# RP1 register map
Vendor: Raspberry Pi; File version: 0.1
CPU: CM3, little endian, MPU, no FPU, 58 interrupts
Registers are access not given, no defined reset value unless marked. A register's access mark holds for its fields unless they carry their own. Offsets are from the block's base; [hi:lo] are bit positions; <NAME> marks a mode.

## UART0
Base 0x40030000
Same registers: UART1 0x40034000, UART2 0x40038000, UART3 0x4003C000, UART4 0x40040000, UART5 0x40044000
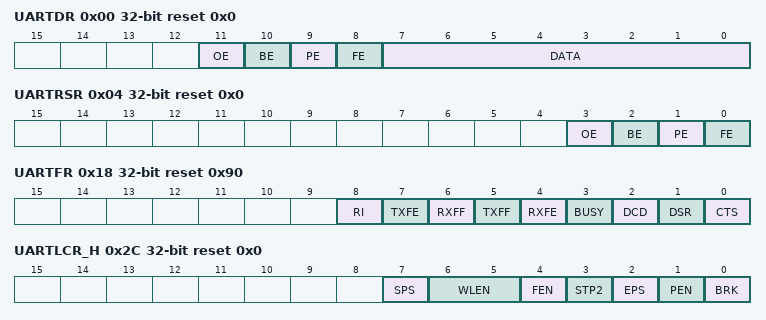
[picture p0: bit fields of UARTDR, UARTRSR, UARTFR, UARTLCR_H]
0x00 UARTDR 32-bit access per field reset 0x0 — Data Register, UARTDR
  [11] OE ro — Overrun error. This bit is set to 1 if data is received and the receive FIFO is already full. This is cleared to 0 once there is an empty space in the FIFO and a new character can be written to it.
  [10] BE ro — Break error. This bit is set to 1 if a break condition was detected, indicating that the received data input was held LOW for longer than a full-word transmission time (defined as start, data, parity and stop bits). In FIFO mode, this error is associated with the character at the top of the FIFO. When a break occurs, only one 0 character is loaded into the FIFO. The next character is only enabled after the receive data input goes to a 1 (marking state), and the next valid start bit is received.
  [9] PE ro — Parity error. When set to 1, it indicates that the parity of the received data character does not match the parity that the EPS and SPS bits in the Line Control Register, UARTLCR_H. In FIFO mode, this error is associated with the character at the top of the FIFO.
  [8] FE ro — Framing error. When set to 1, it indicates that the received character did not have a valid stop bit (a valid stop bit is 1). In FIFO mode, this error is associated with the character at the top of the FIFO.
  [7:0] DATA rw — Receive (read) data character. Transmit (write) data character.
0x04 UARTRSR 32-bit rw reset 0x0 — Receive Status Register/Error Clear Register, UARTRSR/UARTECR
  [3] OE write-1-clears — Overrun error. This bit is set to 1 if data is received and the FIFO is already full. This bit is cleared to 0 by a write to UARTECR. The FIFO contents remain valid because no more data is written when the FIFO is full, only the contents of the shift register are overwritten. The CPU must now read the data, to empty the FIFO.
  [2] BE write-1-clears — Break error. This bit is set to 1 if a break condition was detected, indicating that the received data input was held LOW for longer than a full-word transmission time (defined as start, data, parity, and stop bits). This bit is cleared to 0 after a write to UARTECR. In FIFO mode, this error is associated with the character at the top of the FIFO. When a break occurs, only one 0 character is loaded into the FIFO. The next character is only enabled after the receive data input goes to a 1 (marking state) and the next valid start bit is received.
  [1] PE write-1-clears — Parity error. When set to 1, it indicates that the parity of the received data character does not match the parity that the EPS and SPS bits in the Line Control Register, UARTLCR_H. This bit is cleared to 0 by a write to UARTECR. In FIFO mode, this error is associated with the character at the top of the FIFO.
  [0] FE write-1-clears — Framing error. When set to 1, it indicates that the received character did not have a valid stop bit (a valid stop bit is 1). This bit is cleared to 0 by a write to UARTECR. In FIFO mode, this error is associated with the character at the top of the FIFO.
0x18 UARTFR 32-bit ro reset 0x90 — Flag Register, UARTFR
  [8] RI — Ring indicator. This bit is the complement of the UART ring indicator, nUARTRI, modem status input. That is, the bit is 1 when nUARTRI is LOW.
  [7] TXFE — Transmit FIFO empty. The meaning of this bit depends on the state of the FEN bit in the Line Control Register, UARTLCR_H. If the FIFO is disabled, this bit is set when the transmit holding register is empty. If the FIFO is enabled, the TXFE bit is set when the transmit FIFO is empty. This bit does not indicate if there is data in the transmit shift register.
  [6] RXFF — Receive FIFO full. The meaning of this bit depends on the state of the FEN bit in the UARTLCR_H Register. If the FIFO is disabled, this bit is set when the receive holding register is full. If the FIFO is enabled, the RXFF bit is set when the receive FIFO is full.
  [5] TXFF — Transmit FIFO full. The meaning of this bit depends on the state of the FEN bit in the UARTLCR_H Register. If the FIFO is disabled, this bit is set when the transmit holding register is full. If the FIFO is enabled, the TXFF bit is set when the transmit FIFO is full.
  [4] RXFE — Receive FIFO empty. The meaning of this bit depends on the state of the FEN bit in the UARTLCR_H Register. If the FIFO is disabled, this bit is set when the receive holding register is empty. If the FIFO is enabled, the RXFE bit is set when the receive FIFO is empty.
  [3] BUSY — UART busy. If this bit is set to 1, the UART is busy transmitting data. This bit remains set until the complete byte, including all the stop bits, has been sent from the shift register. This bit is set as soon as the transmit FIFO becomes non-empty, regardless of whether the UART is enabled or not.
  [2] DCD — Data carrier detect. This bit is the complement of the UART data carrier detect, nUARTDCD, modem status input. That is, the bit is 1 when nUARTDCD is LOW.
  [1] DSR — Data set ready. This bit is the complement of the UART data set ready, nUARTDSR, modem status input. That is, the bit is 1 when nUARTDSR is LOW.
  [0] CTS — Clear to send. This bit is the complement of the UART clear to send, nUARTCTS, modem status input. That is, the bit is 1 when nUARTCTS is LOW.
0x20 UARTILPR 32-bit rw reset 0x0 — IrDA Low-Power Counter Register, UARTILPR
  [7:0] ILPDVSR — 8-bit low-power divisor value. These bits are cleared to 0 at reset.
0x24 UARTIBRD 32-bit rw reset 0x0 — Integer Baud Rate Register, UARTIBRD
  [15:0] BAUD_DIVINT — The integer baud rate divisor. These bits are cleared to 0 on reset.
0x28 UARTFBRD 32-bit rw reset 0x0 — Fractional Baud Rate Register, UARTFBRD
  [5:0] BAUD_DIVFRAC — The fractional baud rate divisor. These bits are cleared to 0 on reset.
0x2C UARTLCR_H 32-bit rw reset 0x0 — Line Control Register, UARTLCR_H
  [7] SPS — Stick parity select. 0 = stick parity is disabled 1 = either: * if the EPS bit is 0 then the parity bit is transmitted and checked as a 1 * if the EPS bit is 1 then the parity bit is transmitted and checked as a 0. This bit has no effect when the PEN bit disables parity checking and generation.
  [6:5] WLEN — Word length. These bits indicate the number of data bits transmitted or received in a frame as follows: b11 = 8 bits b10 = 7 bits b01 = 6 bits b00 = 5 bits.
  [4] FEN — Enable FIFOs: 0 = FIFOs are disabled (character mode) that is, the FIFOs become 1-byte-deep holding registers 1 = transmit and receive FIFO buffers are enabled (FIFO mode).
  [3] STP2 — Two stop bits select. If this bit is set to 1, two stop bits are transmitted at the end of the frame. The receive logic does not check for two stop bits being received.
  [2] EPS — Even parity select. Controls the type of parity the UART uses during transmission and reception: 0 = odd parity. The UART generates or checks for an odd number of 1s in the data and parity bits. 1 = even parity. The UART generates or checks for an even number of 1s in the data and parity bits. This bit has no effect when the PEN bit disables parity checking and generation.
  [1] PEN — Parity enable: 0 = parity is disabled and no parity bit added to the data frame 1 = parity checking and generation is enabled.
  [0] BRK — Send break. If this bit is set to 1, a low-level is continually output on the UARTTXD output, after completing transmission of the current character. For the proper execution of the break command, the software must set this bit for at least two complete frames. For normal use, this bit must be cleared to 0.
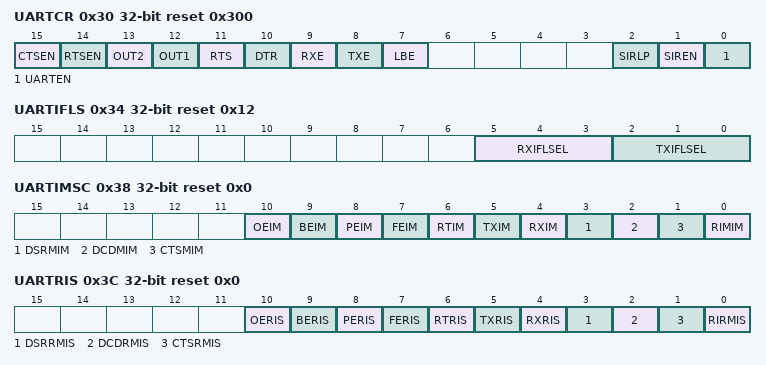
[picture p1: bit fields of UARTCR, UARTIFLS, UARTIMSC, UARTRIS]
0x30 UARTCR 32-bit rw reset 0x300 — Control Register, UARTCR
  [15] CTSEN — CTS hardware flow control enable. If this bit is set to 1, CTS hardware flow control is enabled. Data is only transmitted when the nUARTCTS signal is asserted.
  [14] RTSEN — RTS hardware flow control enable. If this bit is set to 1, RTS hardware flow control is enabled. Data is only requested when there is space in the receive FIFO for it to be received.
  [13] OUT2 — This bit is the complement of the UART Out2 (nUARTOut2) modem status output. That is, when the bit is programmed to a 1, the output is 0. For DTE this can be used as Ring Indicator (RI).
  [12] OUT1 — This bit is the complement of the UART Out1 (nUARTOut1) modem status output. That is, when the bit is programmed to a 1 the output is 0. For DTE this can be used as Data Carrier Detect (DCD).
  [11] RTS — Request to send. This bit is the complement of the UART request to send, nUARTRTS, modem status output. That is, when the bit is programmed to a 1 then nUARTRTS is LOW.
  [10] DTR — Data transmit ready. This bit is the complement of the UART data transmit ready, nUARTDTR, modem status output. That is, when the bit is programmed to a 1 then nUARTDTR is LOW.
  [9] RXE — Receive enable. If this bit is set to 1, the receive section of the UART is enabled. Data reception occurs for either UART signals or SIR signals depending on the setting of the SIREN bit. When the UART is disabled in the middle of reception, it completes the current character before stopping.
  [8] TXE — Transmit enable. If this bit is set to 1, the transmit section of the UART is enabled. Data transmission occurs for either UART signals, or SIR signals depending on the setting of the SIREN bit. When the UART is disabled in the middle of transmission, it completes the current character before stopping.
  [7] LBE — Loopback enable. If this bit is set to 1 and the SIREN bit is set to 1 and the SIRTEST bit in the Test Control Register, UARTTCR is set to 1, then the nSIROUT path is inverted, and fed through to the SIRIN path. The SIRTEST bit in the test register must be set to 1 to override the normal half-duplex SIR operation. This must be the requirement for accessing the test registers during normal operation, and SIRTEST must be cleared to 0 when loopback testing is finished. This feature reduces the amount of external coupling required during system test. If this bit is set to 1, and the SIRTEST bit is set to 0, the UARTTXD path is fed through to the UARTRXD path. In either SIR mode or UART mode, when this bit is set, the modem outputs are also fed through to the modem inputs. This bit is cleared to 0 on reset, to disable loopback.
  [2] SIRLP — SIR low-power IrDA mode. This bit selects the IrDA encoding mode. If this bit is cleared to 0, low-level bits are transmitted as an active high pulse with a width of 3 / 16th of the bit period. If this bit is set to 1, low-level bits are transmitted with a pulse width that is 3 times the period of the IrLPBaud16 input signal, regardless of the selected bit rate. Setting this bit uses less power, but might reduce transmission distances.
  [1] SIREN — SIR enable: 0 = IrDA SIR ENDEC is disabled. nSIROUT remains LOW (no light pulse generated), and signal transitions on SIRIN have no effect. 1 = IrDA SIR ENDEC is enabled. Data is transmitted and received on nSIROUT and SIRIN. UARTTXD remains HIGH, in the marking state. Signal transitions on UARTRXD or modem status inputs have no effect. This bit has no effect if the UARTEN bit disables the UART.
  [0] UARTEN — UART enable: 0 = UART is disabled. If the UART is disabled in the middle of transmission or reception, it completes the current character before stopping. 1 = the UART is enabled. Data transmission and reception occurs for either UART signals or SIR signals depending on the setting of the SIREN bit.
0x34 UARTIFLS 32-bit rw reset 0x12 — Interrupt FIFO Level Select Register, UARTIFLS
  [5:3] RXIFLSEL — Receive interrupt FIFO level select. The trigger points for the receive interrupt are as follows: b000 = Receive FIFO becomes >= 1 / 8 full b001 = Receive FIFO becomes >= 1 / 4 full b010 = Receive FIFO becomes >= 1 / 2 full b011 = Receive FIFO becomes >= 3 / 4 full b100 = Receive FIFO becomes >= 7 / 8 full b101-b111 = reserved.
  [2:0] TXIFLSEL — Transmit interrupt FIFO level select. The trigger points for the transmit interrupt are as follows: b000 = Transmit FIFO becomes <= 1 / 8 full b001 = Transmit FIFO becomes <= 1 / 4 full b010 = Transmit FIFO becomes <= 1 / 2 full b011 = Transmit FIFO becomes <= 3 / 4 full b100 = Transmit FIFO becomes <= 7 / 8 full b101-b111 = reserved.
0x38 UARTIMSC 32-bit rw reset 0x0 — Interrupt Mask Set/Clear Register, UARTIMSC
  [10] OEIM — Overrun error interrupt mask. A read returns the current mask for the UARTOEINTR interrupt. On a write of 1, the mask of the UARTOEINTR interrupt is set. A write of 0 clears the mask.
  [9] BEIM — Break error interrupt mask. A read returns the current mask for the UARTBEINTR interrupt. On a write of 1, the mask of the UARTBEINTR interrupt is set. A write of 0 clears the mask.
  [8] PEIM — Parity error interrupt mask. A read returns the current mask for the UARTPEINTR interrupt. On a write of 1, the mask of the UARTPEINTR interrupt is set. A write of 0 clears the mask.
  [7] FEIM — Framing error interrupt mask. A read returns the current mask for the UARTFEINTR interrupt. On a write of 1, the mask of the UARTFEINTR interrupt is set. A write of 0 clears the mask.
  [6] RTIM — Receive timeout interrupt mask. A read returns the current mask for the UARTRTINTR interrupt. On a write of 1, the mask of the UARTRTINTR interrupt is set. A write of 0 clears the mask.
  [5] TXIM — Transmit interrupt mask. A read returns the current mask for the UARTTXINTR interrupt. On a write of 1, the mask of the UARTTXINTR interrupt is set. A write of 0 clears the mask.
  [4] RXIM — Receive interrupt mask. A read returns the current mask for the UARTRXINTR interrupt. On a write of 1, the mask of the UARTRXINTR interrupt is set. A write of 0 clears the mask.
  [3] DSRMIM — nUARTDSR modem interrupt mask. A read returns the current mask for the UARTDSRINTR interrupt. On a write of 1, the mask of the UARTDSRINTR interrupt is set. A write of 0 clears the mask.
  [2] DCDMIM — nUARTDCD modem interrupt mask. A read returns the current mask for the UARTDCDINTR interrupt. On a write of 1, the mask of the UARTDCDINTR interrupt is set. A write of 0 clears the mask.
  [1] CTSMIM — nUARTCTS modem interrupt mask. A read returns the current mask for the UARTCTSINTR interrupt. On a write of 1, the mask of the UARTCTSINTR interrupt is set. A write of 0 clears the mask.
  [0] RIMIM — nUARTRI modem interrupt mask. A read returns the current mask for the UARTRIINTR interrupt. On a write of 1, the mask of the UARTRIINTR interrupt is set. A write of 0 clears the mask.
0x3C UARTRIS 32-bit ro reset 0x0 — Raw Interrupt Status Register, UARTRIS
  [10] OERIS — Overrun error interrupt status. Returns the raw interrupt state of the UARTOEINTR interrupt.
  [9] BERIS — Break error interrupt status. Returns the raw interrupt state of the UARTBEINTR interrupt.
  [8] PERIS — Parity error interrupt status. Returns the raw interrupt state of the UARTPEINTR interrupt.
  [7] FERIS — Framing error interrupt status. Returns the raw interrupt state of the UARTFEINTR interrupt.
  [6] RTRIS — Receive timeout interrupt status. Returns the raw interrupt state of the UARTRTINTR interrupt. a
  [5] TXRIS — Transmit interrupt status. Returns the raw interrupt state of the UARTTXINTR interrupt.
  [4] RXRIS — Receive interrupt status. Returns the raw interrupt state of the UARTRXINTR interrupt.
  [3] DSRRMIS — nUARTDSR modem interrupt status. Returns the raw interrupt state of the UARTDSRINTR interrupt.
  [2] DCDRMIS — nUARTDCD modem interrupt status. Returns the raw interrupt state of the UARTDCDINTR interrupt.
  [1] CTSRMIS — nUARTCTS modem interrupt status. Returns the raw interrupt state of the UARTCTSINTR interrupt.
  [0] RIRMIS — nUARTRI modem interrupt status. Returns the raw interrupt state of the UARTRIINTR interrupt.
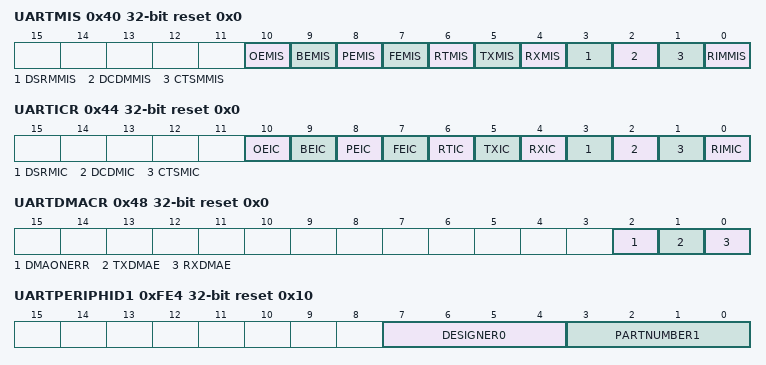
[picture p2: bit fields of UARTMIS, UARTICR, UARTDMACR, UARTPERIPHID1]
0x40 UARTMIS 32-bit ro reset 0x0 — Masked Interrupt Status Register, UARTMIS
  [10] OEMIS — Overrun error masked interrupt status. Returns the masked interrupt state of the UARTOEINTR interrupt.
  [9] BEMIS — Break error masked interrupt status. Returns the masked interrupt state of the UARTBEINTR interrupt.
  [8] PEMIS — Parity error masked interrupt status. Returns the masked interrupt state of the UARTPEINTR interrupt.
  [7] FEMIS — Framing error masked interrupt status. Returns the masked interrupt state of the UARTFEINTR interrupt.
  [6] RTMIS — Receive timeout masked interrupt status. Returns the masked interrupt state of the UARTRTINTR interrupt.
  [5] TXMIS — Transmit masked interrupt status. Returns the masked interrupt state of the UARTTXINTR interrupt.
  [4] RXMIS — Receive masked interrupt status. Returns the masked interrupt state of the UARTRXINTR interrupt.
  [3] DSRMMIS — nUARTDSR modem masked interrupt status. Returns the masked interrupt state of the UARTDSRINTR interrupt.
  [2] DCDMMIS — nUARTDCD modem masked interrupt status. Returns the masked interrupt state of the UARTDCDINTR interrupt.
  [1] CTSMMIS — nUARTCTS modem masked interrupt status. Returns the masked interrupt state of the UARTCTSINTR interrupt.
  [0] RIMMIS — nUARTRI modem masked interrupt status. Returns the masked interrupt state of the UARTRIINTR interrupt.
0x44 UARTICR 32-bit rw reset 0x0 — Interrupt Clear Register, UARTICR
  [10] OEIC write-1-clears — Overrun error interrupt clear. Clears the UARTOEINTR interrupt.
  [9] BEIC write-1-clears — Break error interrupt clear. Clears the UARTBEINTR interrupt.
  [8] PEIC write-1-clears — Parity error interrupt clear. Clears the UARTPEINTR interrupt.
  [7] FEIC write-1-clears — Framing error interrupt clear. Clears the UARTFEINTR interrupt.
  [6] RTIC write-1-clears — Receive timeout interrupt clear. Clears the UARTRTINTR interrupt.
  [5] TXIC write-1-clears — Transmit interrupt clear. Clears the UARTTXINTR interrupt.
  [4] RXIC write-1-clears — Receive interrupt clear. Clears the UARTRXINTR interrupt.
  [3] DSRMIC write-1-clears — nUARTDSR modem interrupt clear. Clears the UARTDSRINTR interrupt.
  [2] DCDMIC write-1-clears — nUARTDCD modem interrupt clear. Clears the UARTDCDINTR interrupt.
  [1] CTSMIC write-1-clears — nUARTCTS modem interrupt clear. Clears the UARTCTSINTR interrupt.
  [0] RIMIC write-1-clears — nUARTRI modem interrupt clear. Clears the UARTRIINTR interrupt.
0x48 UARTDMACR 32-bit rw reset 0x0 — DMA Control Register, UARTDMACR
  [2] DMAONERR — DMA on error. If this bit is set to 1, the DMA receive request outputs, UARTRXDMASREQ or UARTRXDMABREQ, are disabled when the UART error interrupt is asserted.
  [1] TXDMAE — Transmit DMA enable. If this bit is set to 1, DMA for the transmit FIFO is enabled.
  [0] RXDMAE — Receive DMA enable. If this bit is set to 1, DMA for the receive FIFO is enabled.
0xFE0 UARTPERIPHID0 32-bit ro reset 0x11
  [7:0] PARTNUMBER0 — These bits read back as 0x11
0xFE4 UARTPERIPHID1 32-bit ro reset 0x10
  [7:4] DESIGNER0 — These bits read back as 0x1
  [3:0] PARTNUMBER1 — These bits read back as 0x0
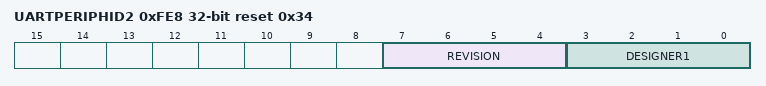
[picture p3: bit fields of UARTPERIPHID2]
0xFE8 UARTPERIPHID2 32-bit ro reset 0x34
  [7:4] REVISION — This field depends on the revision of the UART: r1p0 0x0 r1p1 0x1 r1p3 0x2 r1p4 0x2 r1p5 0x3
  [3:0] DESIGNER1 — These bits read back as 0x4
0xFEC UARTPERIPHID3 32-bit ro reset 0x0
  [7:0] CONFIGURATION — These bits read back as 0x00
0xFF0 UARTPCELLID0 32-bit ro reset 0xD
  [7:0] UARTPCELLID0 — These bits read back as 0x0D
0xFF4 UARTPCELLID1 32-bit ro reset 0xF0
  [7:0] UARTPCELLID1 — These bits read back as 0xF0
0xFF8 UARTPCELLID2 32-bit ro reset 0x5
  [7:0] UARTPCELLID2 — These bits read back as 0x05
0xFFC UARTPCELLID3 32-bit ro reset 0xB1
  [7:0] UARTPCELLID3 — These bits read back as 0xB1
